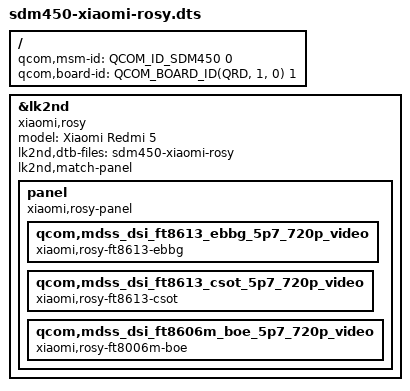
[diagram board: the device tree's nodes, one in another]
// SPDX-License-Identifier: BSD-3-Clause

/dts-v1/;

#include <skeleton64.dtsi>
#include <lk2nd.dtsi>

/ {
	qcom,msm-id = <QCOM_ID_SDM450 0>;
	qcom,board-id = <QCOM_BOARD_ID(QRD, 1, 0) 1>;
};

&lk2nd {
	model = "Xiaomi Redmi 5";
	compatible = "xiaomi,rosy";

	lk2nd,dtb-files = "sdm450-xiaomi-rosy";

	lk2nd,match-panel;
	panel {
		compatible = "xiaomi,rosy-panel", "lk2nd,panel";

		qcom,mdss_dsi_ft8613_ebbg_5p7_720p_video {
			compatible = "xiaomi,rosy-ft8613-ebbg";
		};
		qcom,mdss_dsi_ft8613_csot_5p7_720p_video {
			compatible = "xiaomi,rosy-ft8613-csot";
		};
		qcom,mdss_dsi_ft8606m_boe_5p7_720p_video {
			compatible = "xiaomi,rosy-ft8006m-boe";
		};
	};
};
